# RTS5921 register map
Vendor: Realtek Semiconductor Corp.; Series: RTS5921 Series; File version: 0.01
CPU: ARMV8MBL r0p0, little endian, MPU, no FPU, VTOR, 3 interrupt priority bits
Registers are 32-bit, read-write, reset 0x0 unless marked. A register's access mark holds for its fields unless they carry their own. Offsets are from the block's base; [hi:lo] are bit positions; {n}, {i} and the like mark numbered series; 'fields as' and 'values as' point back to an identical list.

## DMA — Realtek RXI-350 DMA Controller
Base 0x40002000
{0x0+0x58*i} SAR{i} (i=0..7) — Channel {i} Source Address Register
{0x4+0x58*i} CURR_SAR{i} ro (i=0..7) — Channel {i} Current Source Address Register
{0x8+0x58*i} DAR{i} (i=0..7) — Channel {i} Destination Address Register
{0xC+0x58*i} CURR_DAR{i} ro (i=0..7) — Channel {i} Current Destination Address Register
{0x10+0x58*i} LLP{i}_L (i=0..7) — Channel {i} low-32bits Linked List Pointer Register
{0x14+0x58*i} LLP{i}_H (i=0..7) — Channel {i} high-32bits Linked List Pointer Register
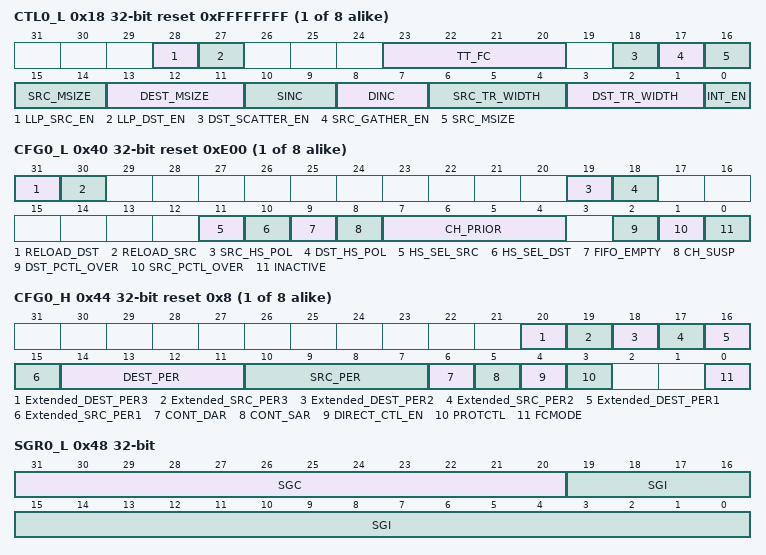
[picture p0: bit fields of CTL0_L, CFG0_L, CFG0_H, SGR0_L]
{0x18+0x58*i} CTL{i}_L reset 0xFFFFFFFF (i=0..7) — Channel {i} low-32bits Control Register
  [28] LLP_SRC_EN — Enables block chaining on the source side if high and LLPx_L.LOC is non-zero.
  [27] LLP_DST_EN — Enables block chaining on the destination side if high and LLPx_L.LOC is non-zero.
  [23:20] TT_FC — Transfer Type and Flow Control. Supports multiple transfer types, with specific flow control.
  [18] DST_SCATTER_EN — Enables scatter on the destination side if conditions in address control align.
  [17] SRC_GATHER_EN — Enables gather on the source side if conditions in address control align.
  [16:14] SRC_MSIZE — Number of data items per source burst transaction.
  [13:11] DEST_MSIZE — Number of data items per destination burst transaction.
  [10:9] SINC — Source Address Increment. Indicates increment behavior for source address.
  [8:7] DINC — Destination Address Increment. Indicates increment behavior for destination address.
  [6:4] SRC_TR_WIDTH — Source Transfer Width. Specifies width of data transfer from source.
  [3:1] DST_TR_WIDTH — Destination Transfer Width. Specifies width of data transfer to destination.
  [0] INT_EN — Interrupt Enable Bit. Globally enables interrupt sources for the channel.
0x1C CTL0_H reset 0xFFFFFFFF — Channel 0 high-32bits Control Register
  [31:0] BLOCK_TS — Block Transfer Size. Configures single transaction counts per block, subject to AXI beat mapping.
{0x20+0x58*i} BLK_COUNTER_REG{i} (i=0..7) — Channel {i} 32bits Block Counter Register
{0x24+0x58*i} REPEAT_PATTERN{i} (i=0..7) — Channel {i} 32bits Memory Repeat Pattern Register
{0x40+0x58*i} CFG{i}_L reset 0xE00 (i=0..7) — Channel {i} low-32bits Configuration Register
  [31] RELOAD_DST — Automatic Destination Reload. Reloads DARx register from its initial value at the end of every block for multi-block transfers.
  [30] RELOAD_SRC — Automatic Source Reload. Reloads SARx register from its initial value at the end of every block for multi-block transfers.
  [19] SRC_HS_POL ro — Source Handshaking Interface Polarity.
  [18] DST_HS_POL ro — Destination Handshaking Interface Polarity.
  [11] HS_SEL_SRC — Source Software or Hardware Handshaking Select.
  [10] HS_SEL_DST — Destination Software or Hardware Handshaking Select.
  [9] FIFO_EMPTY — Indicates if there is data left in the channel FIFO.
  [8] CH_SUSP — Channel Suspend. Suspends all DMA data transfers from the source until this bit is cleared.
  [7:4] CH_PRIOR — Channel priority configuration.
  [2] DST_PCTL_OVER ro — DMA destination bus protocol finish indicator.
  [1] SRC_PCTL_OVER ro — DMA Source bus protocol finish indicator.
  [0] INACTIVE ro — Indicates if the channel is inactive.
{0x44+0x58*i} CFG{i}_H reset 0x8 (i=0..7) — Channel {i} high-32bits Configuration Register
  [20] Extended_DEST_PER3 — Extended 6th bit of DEST_PER if hardware handshake interfaces are configured to (64, 128].
  [19] Extended_SRC_PER3 — Extended 6th bit of SRC_PER if hardware handshake interfaces are configured to (64, 128].
  [18] Extended_DEST_PER2 — Extended 5th bit of DEST_PER if hardware handshake interfaces are configured to (32, 128].
  [17] Extended_SRC_PER2 — Extended 5th bit of SRC_PER if hardware handshake interfaces are configured to (32, 128].
  [16] Extended_DEST_PER1 — Extended 4th bit of DEST_PER if hardware handshake interfaces are configured to (16, 128].
  [15] Extended_SRC_PER1 — Extended 4th bit of SRC_PER if hardware handshake interfaces are configured to (16, 128].
  [14:11] DEST_PER — Assigns a hardware handshaking interface for the destination of channel x.
  [10:7] SRC_PER — Assigns a hardware handshaking interface for the source of channel x.
  [6] CONT_DAR — Continuous for DAR between single block.
  [5] CONT_SAR — Continuous for SAR between single block.
  [4] DIRECT_CTL_EN — Direct Control for channel enabling.
  [3] PROTCTL — Protection Control bit for secure transfers.
  [0] FCMODE — Flow Control Mode.
0x48 SGR0_L — Channel 0 low-32bits Source Gather Register
  [31:20] SGC — Source gather count. Source contiguous transfer count between successive gather boundaries.
  [19:0] SGI — Source gather interval.
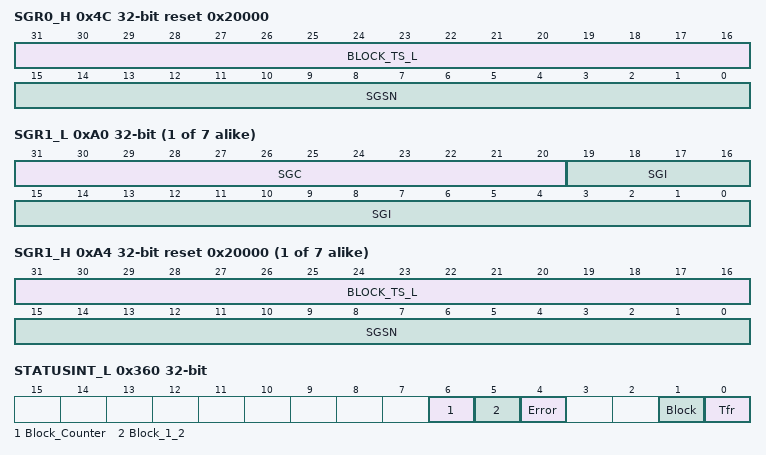
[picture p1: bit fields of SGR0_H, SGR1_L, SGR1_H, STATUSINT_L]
0x4C SGR0_H reset 0x20000 — Channel 0 high-32bits Source Gather Register
  [31:16] BLOCK_TS_L ro — Low 16-bits of Block Transfer Size. Indicates the total number of single transactions per block transfer.
  [15:0] SGSN — Source gather circular streaming number. Enables circular gather feature if set greater than 1.
{0x50+0x58*i} DSR{i}_L (i=0..5) — Channel {i} low-32bits Destination Scatter Register
0x54 DSR0_H reset 0x20000 — Channel 0 high-32bits Destination Scatter Register
0x74 CTL1_H reset 0xFFFFFFFF — Channel 1 low-32bits Control Register
  fields as CTL0_H
{0x48+0x58*i} SGR{i}_L (i=1..7) — Channel {i} Source Gather Configuration Register
  fields as SGR0_L
{0x4C+0x58*i} SGR{i}_H reset 0x20000 (i=1..7) — Channel {i} Source Gather High Configuration Register
  fields as SGR0_H
{0x54+0x58*i} DSR{i}_H (i=1..5) — Channel {i} high-32bits Destination Scatter Register
{0x1C+0x58*i} CTL{i}_H reset 0xFFFFFFFF (i=2..7) — Channel {i} high-32bits Control Register
  fields as CTL0_H
0x2B8 DSR7_L — Channel 7 low-32bits Destination Scatter Register
0x2BC DSR7_H — Channel 7 high-32bits Destination Scatter Register
0x2C0 RAWTFR_L ro — Raw Status for IntTfr Interrupt
0x2C4 RAWTFR_H ro — Raw Status for Blk Counter Register
0x2C8 RAWBLOCK_L ro — Raw Status for IntBlock Interrupt
0x2CC RAWBLOCK_H ro — Raw Status for Int_1_2_Block if defined
0x2D0 RAWERR_L ro — Raw Status for IntErr Interrupt (protocol error)
0x2E4 RAWERR_H ro — Raw Status for non-secure access secure register error if defined
0x2EC STATUSTFR_L ro — Status for IntTfr Interrupt
0x2F0 STATUSTFR_H ro — Status for Blk Counter Interrupt
0x2F8 STATUSBLOCK_L ro — Status for IntBlock Interrupt
0x308 STATUSERR_L ro — Status for IntErr Interrupt (protocol error)
0x310 MASKTFR_L — Mask for IntTfr Interrupt
0x314 MASKTFR_H — Mask for Blk Counter Interrupt
0x318 MASKBLOCK_L — Mask for IntBlock Interrupt
0x31C MASKBLOCK_H — Mask for Int_1_2_Block if defined
0x330 MASKERR_L — Mask for IntErr Interrupt
0x334 MASKERR_H — Mask for non-secure access secure register error if defined
0x338 CLEARTFR — MClear for IntTfr Interrupt
0x340 CLEARBLOCK — MClear for IntBlock Interrupt
0x358 CLEARERR — MClear for IntErr Interrupt
0x360 STATUSINT_L ro — Combined Interrupt Status (Low) Register
  [6] Block_Counter — Reserved Condition: OR of the StatusTfr_H register contents if DMAC_CHx_SUPPORT_BLK_COUNTER is defined. Otherwise, 0.
  [5] Block_1_2 — Reserved Condition: OR of the Status_1_2_Block register contents if DMAC_1_2_BLK_TRANSFER_INT is defined. Otherwise, 0.
  [4] Error — OR of the contents of StatusErr register.
  [1] Block — OR of the contents of StatusBlock register.
  [0] Tfr — OR of the contents of StatusTfr_L register.
0x364 STATUSINT_H ro — Combined Interrupt Status (High) Register
0x398 DMACFGREG — DMA Configuration Register
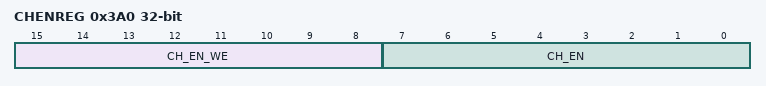
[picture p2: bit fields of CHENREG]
0x3A0 CHENREG — DMA low-32bits Channel Enable Register
  [15:8] CH_EN_WE — Channel enable write enable.
  [7:0] CH_EN — Enables/Disables the channel. Setting this bit enables a channel; clearing it disables the channel. - 0 = Disable the Channel - 1 = Enable the Channel The CHENREG_L.CH_EN bit is automatically cleared by hardware after the last AXI transfer of the DMA transfer to the destination has completed. Software can poll this bit to determine when the channel is available for a new DMA transfer.
